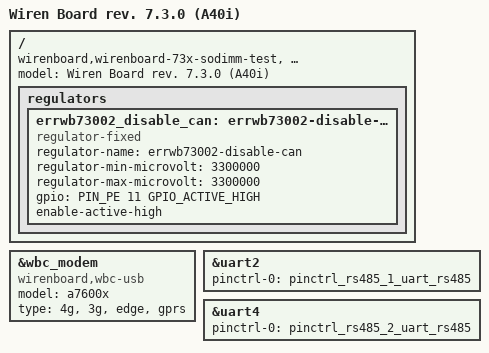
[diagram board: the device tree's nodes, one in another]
/dts-v1/;
#include "sun8i-r40-wirenboard730.dts"

/* CAN is disabled on WB 7.3
	see https://wirenboard.com/wiki/WB_7:_Errata (ERRWB73002) for details
*/

/ {
	/* wirenboard-720 is left for userspace compatibility */
	model = "Wiren Board rev. 7.3.0 (A40i)";
	compatible = "wirenboard,wirenboard-73x-sodimm-test, wirenboard,wirenboard-730", "wirenboard,wirenboard-73x", "wirenboard,wirenboard-72x",  "wirenboard,wirenboard-720", "wirenboard,wirenboard-7xx", "allwinner,sun8i-r40";

	regulators {
		/* GPIO hogs crash kernel on sunxi, so use dummy regulator */
		errwb73002_disable_can: errwb73002-disable-can {
			compatible = "regulator-fixed";
			regulator-name = "errwb73002-disable-can";
			regulator-min-microvolt = <3300000>;
			regulator-max-microvolt = <3300000>;
			gpio = <PIN_PE 11 GPIO_ACTIVE_HIGH>;
			enable-active-high;
		};
	};
};

&wbc_modem {
	status = "okay";
	model = "a7600x";
	type = "4g", "3g", "edge", "gprs";
	compatible = "wirenboard,wbc-usb";
};

&uart2 {
	pinctrl-0 = <&pinctrl_rs485_1_uart_rs485>;
	status = "okay";
};

&uart4 {
	status = "okay";
	pinctrl-0 = <&pinctrl_rs485_2_uart_rs485>;
};
